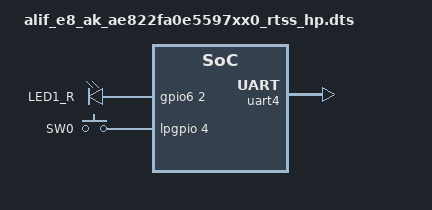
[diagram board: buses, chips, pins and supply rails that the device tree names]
/* Copyright (c) 2025 Alif Semiconductor
 *
 * SPDX-License-Identifier: Apache-2.0
 */

/dts-v1/;

#include <alif/ensemble/common/e8_appkit.dtsi>
#include <alif/ensemble/common/ensemble_rtss_hp.dtsi>
#include "../common/ensemble-pinctrl.dtsi"

/ {
	compatible = "arm,alif-e8-ak-ae822fa0e5597xx0-rtss-hp";
	#address-cells = <1>;
	#size-cells = <1>;

	chosen {
		zephyr,flash = &mram_storage;
		zephyr,code-partition = &slot0_partition;
		zephyr,sram = &dtcm;
		zephyr,console = &uart4;
		zephyr,shell-uart = &uart4;
		zephyr,uart-mcumgr = &uart4;
	};

	aliases {
		led0 = &aled0;
		sw0 = &button0;
		watchdog0 = &wdog0;
		rtsshemhu0r = &rtsshp_rtsshe_mhu0_r;
		rtsshemhu0s = &rtsshe_rtsshp_mhu0_s;
		rtsshemhu1r = &rtsshp_rtsshe_mhu1_r;
		rtsshemhu1s = &rtsshe_rtsshp_mhu1_s;
	};

	leds {
		compatible = "gpio-leds";
		aled0: led_0 {
			gpios = <&gpio6 2 0>;
			label = "LED1_R";
		};
	};
	buttons {
		compatible = "gpio-keys";
		button0: button_0 {
			gpios = <&lpgpio 4 0>;
			label = "SW0";
		};
	};
};

&gpio6 {
	status = "okay";
};

&uart4 {
	status = "okay";
};
